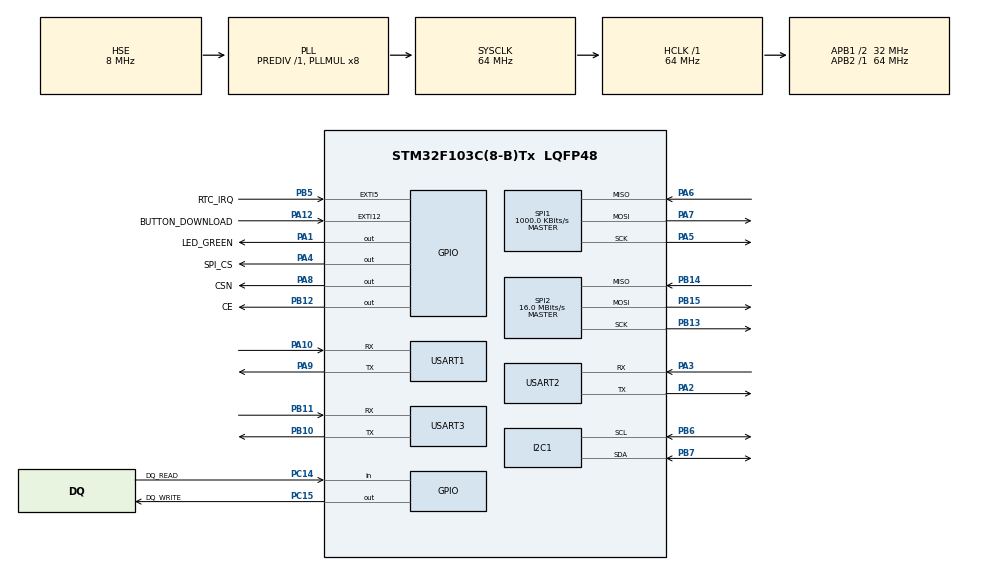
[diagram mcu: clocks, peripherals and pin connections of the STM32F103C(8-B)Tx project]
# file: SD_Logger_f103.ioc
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IWDG.Prescaler=IWDG_PRESCALER_64
Mcu.Family=STM32F1
Mcu.Name=STM32F103C(8-B)Tx
Mcu.Package=LQFP48
NVIC.EXTI15_10_IRQn=true\:0\:0\:false\:false\:true\:true\:true
NVIC.EXTI9_5_IRQn=true\:0\:0\:false\:false\:true\:true\:true
NVIC.PriorityGroup=NVIC_PRIORITYGROUP_4
PA1.GPIO_Label=LED_GREEN
PA1.GPIO_ModeDefaultOutputPP=GPIO_MODE_OUTPUT_OD
PA1.Signal=GPIO_Output
PA10.Mode=Asynchronous
PA10.Signal=USART1_RX
PA12.GPIO_Label=BUTTON_DOWNLOAD
PA12.GPIO_ModeDefaultEXTI=GPIO_MODE_IT_FALLING
PA12.GPIO_PuPd=GPIO_PULLUP
PA12.Signal=GPXTI12
PA13.Mode=Serial_Wire
PA13.Signal=SYS_JTMS-SWDIO
PA14.Mode=Serial_Wire
PA14.Signal=SYS_JTCK-SWCLK
PA2.Mode=Asynchronous
PA2.Signal=USART2_TX
PA3.Mode=Asynchronous
PA3.Signal=USART2_RX
PA4.GPIO_Label=SPI_CS
PA4.GPIO_PuPd=GPIO_PULLUP
PA4.Signal=GPIO_Output
PA5.Mode=Full_Duplex_Master
PA5.Signal=SPI1_SCK
PA6.Mode=Full_Duplex_Master
PA6.Signal=SPI1_MISO
PA7.Mode=Full_Duplex_Master
PA7.Signal=SPI1_MOSI
PA8.GPIO_Label=CSN
PA8.GPIO_PuPd=GPIO_PULLUP
PA8.Signal=GPIO_Output
PA9.Mode=Asynchronous
PA9.Signal=USART1_TX
PB10.Mode=Asynchronous
PB10.Signal=USART3_TX
PB11.Mode=Asynchronous
PB11.Signal=USART3_RX
PB12.GPIO_Label=CE
PB12.GPIO_PuPd=GPIO_PULLUP
PB12.Signal=GPIO_Output
PB13.Mode=Full_Duplex_Master
PB13.Signal=SPI2_SCK
PB14.Mode=Full_Duplex_Master
PB14.Signal=SPI2_MISO
PB15.Mode=Full_Duplex_Master
PB15.Signal=SPI2_MOSI
PB5.GPIO_Label=RTC_IRQ
PB5.GPIO_ModeDefaultEXTI=GPIO_MODE_IT_FALLING
PB5.GPIO_PuPd=GPIO_PULLUP
PB5.Signal=GPXTI5
PB6.Mode=I2C
PB6.Signal=I2C1_SCL
PB7.Mode=I2C
PB7.Signal=I2C1_SDA
PC14-OSC32_IN.GPIO_Label=DQ_READ
PC14-OSC32_IN.GPIO_PuPd=GPIO_PULLUP
PC14-OSC32_IN.Signal=GPIO_Input
PC15-OSC32_OUT.GPIO_Label=DQ_WRITE
PC15-OSC32_OUT.GPIO_ModeDefaultOutputPP=GPIO_MODE_OUTPUT_OD
PC15-OSC32_OUT.GPIO_PuPd=GPIO_PULLUP
PC15-OSC32_OUT.GPIO_Speed=GPIO_SPEED_FREQ_HIGH
PC15-OSC32_OUT.PinState=GPIO_PIN_SET
PC15-OSC32_OUT.Signal=GPIO_Output
PD0-OSC_IN.Mode=HSE-External-Oscillator
PD0-OSC_IN.Signal=RCC_OSC_IN
PD1-OSC_OUT.Mode=HSE-External-Oscillator
PD1-OSC_OUT.Signal=RCC_OSC_OUT
ProjectManager.HeapSize=0x200
ProjectManager.StackSize=0x400
ProjectManager.TargetToolchain=SW4STM32
RCC.AHBFreq_Value=64000000
RCC.APB1CLKDivider=RCC_HCLK_DIV2
RCC.APB1Freq_Value=32000000
RCC.APB1TimFreq_Value=64000000
RCC.APB2Freq_Value=64000000
RCC.APB2TimFreq_Value=64000000
RCC.HCLKFreq_Value=64000000
RCC.PLLMUL=RCC_PLL_MUL8
RCC.PLLSourceVirtual=RCC_PLLSOURCE_HSE
RCC.SYSCLKFreq_VALUE=64000000
RCC.SYSCLKSource=RCC_SYSCLKSOURCE_PLLCLK
RCC.USBFreq_Value=64000000
SPI1.BaudRatePrescaler=SPI_BAUDRATEPRESCALER_64
SPI1.CalculateBaudRate=1000.0 KBits/s
SPI1.Direction=SPI_DIRECTION_2LINES
SPI1.Mode=SPI_MODE_MASTER
SPI1.VirtualType=VM_MASTER
SPI2.CalculateBaudRate=16.0 MBits/s
SPI2.Direction=SPI_DIRECTION_2LINES
SPI2.Mode=SPI_MODE_MASTER
SPI2.VirtualType=VM_MASTER
USART1.VirtualMode=VM_ASYNC
USART2.VirtualMode=VM_ASYNC
USART3.VirtualMode=VM_ASYNC
VP_FATFS_VS_Generic.Mode=User_defined
VP_IWDG_VS_IWDG.Mode=IWDG_Activate
VP_RTC_VS_RTC_Activate.Mode=RTC_Enabled
VP_RTC_VS_RTC_Calendar.Mode=RTC_Calendar
board=custom

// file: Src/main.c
/* USER CODE BEGIN Header */
/**
  ******************************************************************************
  * @file           : main.c
  * @brief          : Main program body
  ******************************************************************************
  * @attention
  *
  * <h2><center>&copy; Copyright (c) 2020 STMicroelectronics.
  * All rights reserved.</center></h2>
  *
  * This software component is licensed by ST under BSD 3-Clause license,
  * the "License"; You may not use this file except in compliance with the
  * License. You may obtain a copy of the License at:
  *                        opensource.org/licenses/BSD-3-Clause
  *
  ******************************************************************************
  */
/* USER CODE END Header */

#include "main.h"
#include "fatfs.h"
#include "i2c.h"
#include "iwdg.h"
#include "rtc.h"
#include "spi.h"
#include "usart.h"
#include "gpio.h"

/* USER CODE BEGIN Includes */

	#include "sd_logger_sm.h"

/* USER CODE END Includes */

void SystemClock_Config(void);

int main(void)
{

  /* MCU Configuration--------------------------------------------------------*/

  /* Reset of all peripherals, Initializes the Flash interface and the Systick. */
  HAL_Init();

  /* Configure the system clock */
  SystemClock_Config();

  /* Initialize all configured peripherals */
  MX_GPIO_Init();
  MX_USART1_UART_Init();
  MX_SPI1_Init();
  MX_FATFS_Init();
  MX_I2C1_Init();
  MX_RTC_Init();
  MX_IWDG_Init();
  MX_USART2_UART_Init();
  MX_USART3_UART_Init();
  MX_SPI2_Init();
  /* USER CODE BEGIN 2 */

  	  SD_Logger_Init();

  /* USER CODE END 2 */

  /* Infinite loop */
  /* USER CODE BEGIN WHILE */
  while (1)
  {
	  SD_Logger_Main();

    /* USER CODE END WHILE */

  }
}

void SystemClock_Config(void)
{
  RCC_OscInitTypeDef RCC_OscInitStruct = {0};
  RCC_ClkInitTypeDef RCC_ClkInitStruct = {0};
  RCC_PeriphCLKInitTypeDef PeriphClkInit = {0};

  /** Initializes the CPU, AHB and APB busses clocks
  */
  RCC_OscInitStruct.OscillatorType = RCC_OSCILLATORTYPE_LSI|RCC_OSCILLATORTYPE_HSE;
  RCC_OscInitStruct.HSEState = RCC_HSE_ON;
  RCC_OscInitStruct.HSEPredivValue = RCC_HSE_PREDIV_DIV1;
  RCC_OscInitStruct.HSIState = RCC_HSI_ON;
  RCC_OscInitStruct.LSIState = RCC_LSI_ON;
  RCC_OscInitStruct.PLL.PLLState = RCC_PLL_ON;
  RCC_OscInitStruct.PLL.PLLSource = RCC_PLLSOURCE_HSE;
  RCC_OscInitStruct.PLL.PLLMUL = RCC_PLL_MUL8;
  if (HAL_RCC_OscConfig(&RCC_OscInitStruct) != HAL_OK)
  {
    Error_Handler();
  }
  /** Initializes the CPU, AHB and APB busses clocks
  */
  RCC_ClkInitStruct.ClockType = RCC_CLOCKTYPE_HCLK|RCC_CLOCKTYPE_SYSCLK
                              |RCC_CLOCKTYPE_PCLK1|RCC_CLOCKTYPE_PCLK2;
  RCC_ClkInitStruct.SYSCLKSource = RCC_SYSCLKSOURCE_PLLCLK;
  RCC_ClkInitStruct.AHBCLKDivider = RCC_SYSCLK_DIV1;
  RCC_ClkInitStruct.APB1CLKDivider = RCC_HCLK_DIV2;
  RCC_ClkInitStruct.APB2CLKDivider = RCC_HCLK_DIV1;

  if (HAL_RCC_ClockConfig(&RCC_ClkInitStruct, FLASH_LATENCY_2) != HAL_OK)
  {
    Error_Handler();
  }
  PeriphClkInit.PeriphClockSelection = RCC_PERIPHCLK_RTC;
  PeriphClkInit.RTCClockSelection = RCC_RTCCLKSOURCE_LSI;
  if (HAL_RCCEx_PeriphCLKConfig(&PeriphClkInit) != HAL_OK)
  {
    Error_Handler();
  }
}

void Error_Handler(void)
{
}

/************************ (C) COPYRIGHT STMicroelectronics *****END OF FILE****/
